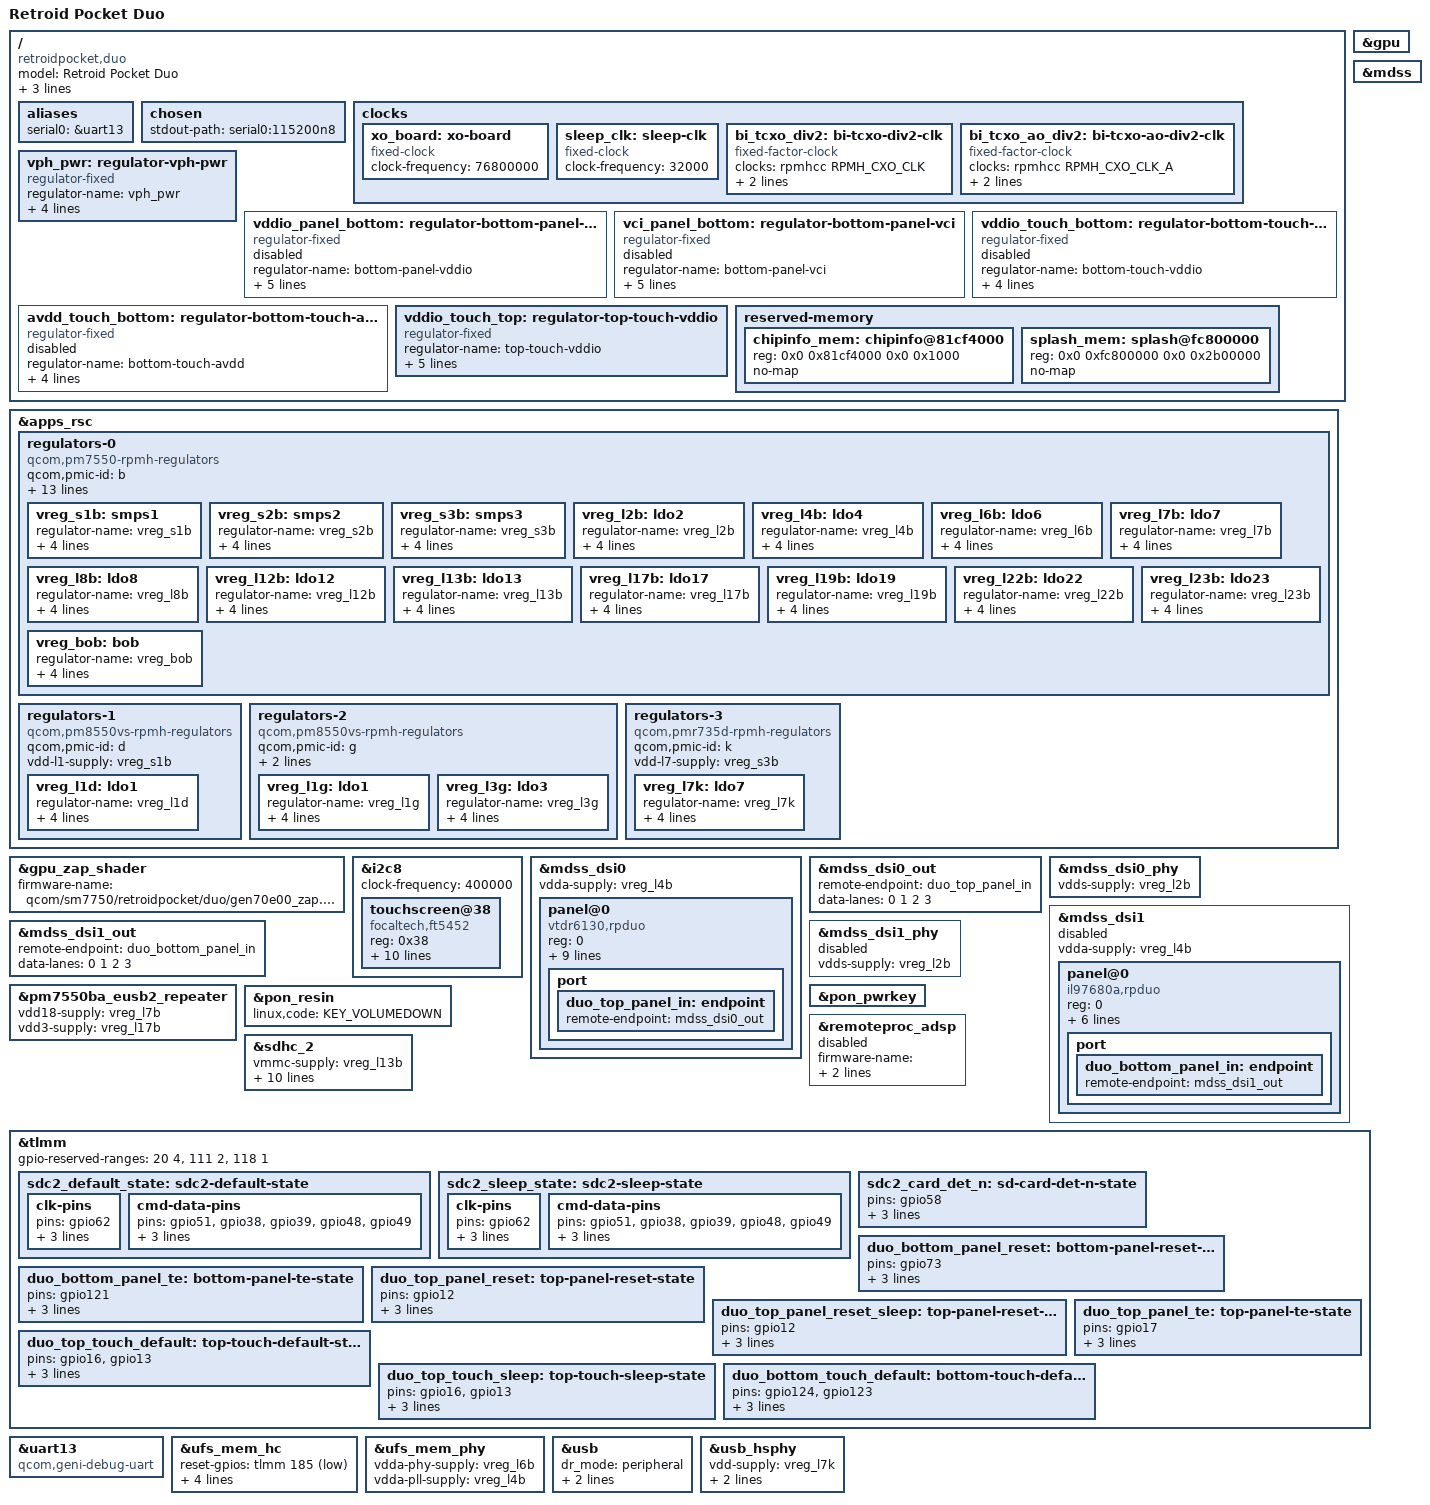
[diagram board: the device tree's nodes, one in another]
// SPDX-License-Identifier: BSD-3-Clause
/*
 * Copyright (c) Qualcomm Technologies, Inc. and/or its subsidiaries.
 * Copyright (c) 2026 Armada contributors.
 *
 */

/dts-v1/;

#include <dt-bindings/gpio/gpio.h>
#include <dt-bindings/input/linux-event-codes.h>
#include <dt-bindings/interrupt-controller/irq.h>
#include <dt-bindings/regulator/qcom,rpmh-regulator.h>
#include "eliza.dtsi"
#include "pm7550ba-eliza.dtsi"

#define spmi_bus spmi_bus0
#include "pmk8550.dtsi"
#undef spmi_bus

/ {
	model = "Retroid Pocket Duo";
	compatible = "retroidpocket,duo", "qcom,eliza";
	chassis-type = "handset";

	qcom,msm-id = <732 0x10000>;
	qcom,board-id = <0x10008 1>;

	aliases {
		serial0 = &uart13;
	};

	chosen {
		stdout-path = "serial0:115200n8";
	};

	clocks {
		xo_board: xo-board {
			compatible = "fixed-clock";
			clock-frequency = <76800000>;
			#clock-cells = <0>;
		};

		sleep_clk: sleep-clk {
			compatible = "fixed-clock";
			clock-frequency = <32000>;
			#clock-cells = <0>;
		};

		bi_tcxo_div2: bi-tcxo-div2-clk {
			compatible = "fixed-factor-clock";
			#clock-cells = <0>;

			clocks = <&rpmhcc RPMH_CXO_CLK>;
			clock-mult = <1>;
			clock-div = <2>;
		};

		bi_tcxo_ao_div2: bi-tcxo-ao-div2-clk {
			compatible = "fixed-factor-clock";
			#clock-cells = <0>;

			clocks = <&rpmhcc RPMH_CXO_CLK_A>;
			clock-mult = <1>;
			clock-div = <2>;
		};
	};

	vph_pwr: regulator-vph-pwr {
		compatible = "regulator-fixed";
		regulator-name = "vph_pwr";
		regulator-min-microvolt = <3700000>;
		regulator-max-microvolt = <3700000>;
		regulator-always-on;
		regulator-boot-on;
	};

	vddio_panel_bottom: regulator-bottom-panel-vddio {
		compatible = "regulator-fixed";
		regulator-name = "bottom-panel-vddio";
		regulator-min-microvolt = <1800000>;
		regulator-max-microvolt = <1800000>;
		gpio = <&tlmm 69 GPIO_ACTIVE_HIGH>;
		enable-active-high;
		startup-delay-us = <233>;
		status = "disabled";
	};

	vci_panel_bottom: regulator-bottom-panel-vci {
		compatible = "regulator-fixed";
		regulator-name = "bottom-panel-vci";
		regulator-min-microvolt = <3000000>;
		regulator-max-microvolt = <3000000>;
		gpio = <&tlmm 70 GPIO_ACTIVE_HIGH>;
		enable-active-high;
		startup-delay-us = <233>;
		status = "disabled";
	};

	vddio_touch_bottom: regulator-bottom-touch-vddio {
		compatible = "regulator-fixed";
		regulator-name = "bottom-touch-vddio";
		regulator-min-microvolt = <1800000>;
		regulator-max-microvolt = <1800000>;
		gpio = <&tlmm 71 GPIO_ACTIVE_HIGH>;
		enable-active-high;
		status = "disabled";
	};

	avdd_touch_bottom: regulator-bottom-touch-avdd {
		compatible = "regulator-fixed";
		regulator-name = "bottom-touch-avdd";
		regulator-min-microvolt = <3000000>;
		regulator-max-microvolt = <3000000>;
		gpio = <&tlmm 72 GPIO_ACTIVE_HIGH>;
		enable-active-high;
		status = "disabled";
	};

	vddio_touch_top: regulator-top-touch-vddio {
		compatible = "regulator-fixed";
		regulator-name = "top-touch-vddio";
		regulator-min-microvolt = <1800000>;
		regulator-max-microvolt = <1800000>;
		gpio = <&tlmm 74 GPIO_ACTIVE_HIGH>;
		enable-active-high;
		startup-delay-us = <233>;
	};

	reserved-memory {
		chipinfo_mem: chipinfo@81cf4000 {
			reg = <0x0 0x81cf4000 0x0 0x1000>;
			no-map;
		};

		splash_mem: splash@fc800000 {
			reg = <0x0 0xfc800000 0x0 0x2b00000>;
			no-map;
		};
	};
};

/*
 * LDO parent wiring follows Eliza MTP and is unverified on the Duo,
 * except for L1D's S1B parent, which Android explicitly identifies.
 */
&apps_rsc {
	regulators-0 {
		compatible = "qcom,pm7550-rpmh-regulators";
		qcom,pmic-id = "b";

		vdd-l2-l3-supply = <&vreg_s3b>;
		vdd-l4-l5-supply = <&vreg_s2b>;
		vdd-l6-supply = <&vreg_s2b>;
		vdd-l7-supply = <&vreg_s1b>;
		vdd-l8-supply = <&vreg_s1b>;
		vdd-l12-l14-supply = <&vreg_bob>;
		vdd-l13-l16-supply = <&vreg_bob>;
		vdd-l15-l17-l18-l19-l20-l21-l22-l23-supply = <&vreg_bob>;
		vdd-s1-supply = <&vph_pwr>;
		vdd-s2-supply = <&vph_pwr>;
		vdd-s3-supply = <&vph_pwr>;
		vdd-bob-supply = <&vph_pwr>;

		vreg_s1b: smps1 {
			regulator-name = "vreg_s1b";
			regulator-min-microvolt = <1856000>;
			regulator-max-microvolt = <2040000>;
			regulator-initial-mode = <RPMH_REGULATOR_MODE_HPM>;
		};

		vreg_s2b: smps2 {
			regulator-name = "vreg_s2b";
			regulator-min-microvolt = <1256000>;
			regulator-max-microvolt = <1408000>;
			regulator-initial-mode = <RPMH_REGULATOR_MODE_HPM>;
		};

		vreg_s3b: smps3 {
			regulator-name = "vreg_s3b";
			regulator-min-microvolt = <880000>;
			regulator-max-microvolt = <1040000>;
			regulator-initial-mode = <RPMH_REGULATOR_MODE_HPM>;
		};

		vreg_l2b: ldo2 {
			regulator-name = "vreg_l2b";
			regulator-min-microvolt = <880000>;
			regulator-max-microvolt = <950000>;
			regulator-initial-mode = <RPMH_REGULATOR_MODE_HPM>;
		};

		vreg_l4b: ldo4 {
			regulator-name = "vreg_l4b";
			regulator-min-microvolt = <1200000>;
			regulator-max-microvolt = <1200000>;
			regulator-initial-mode = <RPMH_REGULATOR_MODE_HPM>;
		};

		vreg_l6b: ldo6 {
			regulator-name = "vreg_l6b";
			regulator-min-microvolt = <866000>;
			regulator-max-microvolt = <958000>;
			regulator-initial-mode = <RPMH_REGULATOR_MODE_HPM>;
		};

		vreg_l7b: ldo7 {
			regulator-name = "vreg_l7b";
			regulator-min-microvolt = <1800000>;
			regulator-max-microvolt = <2000000>;
			regulator-initial-mode = <RPMH_REGULATOR_MODE_HPM>;
		};

		vreg_l8b: ldo8 {
			regulator-name = "vreg_l8b";
			regulator-min-microvolt = <1650000>;
			regulator-max-microvolt = <2000000>;
			regulator-initial-mode = <RPMH_REGULATOR_MODE_HPM>;
		};

		vreg_l12b: ldo12 {
			regulator-name = "vreg_l12b";
			regulator-min-microvolt = <2952000>;
			regulator-max-microvolt = <2952000>;
			regulator-initial-mode = <RPMH_REGULATOR_MODE_HPM>;
		};

		vreg_l13b: ldo13 {
			regulator-name = "vreg_l13b";
			regulator-min-microvolt = <2960000>;
			regulator-max-microvolt = <2960000>;
			regulator-initial-mode = <RPMH_REGULATOR_MODE_HPM>;
		};

		vreg_l17b: ldo17 {
			regulator-name = "vreg_l17b";
			regulator-min-microvolt = <3075000>;
			regulator-max-microvolt = <3300000>;
			regulator-initial-mode = <RPMH_REGULATOR_MODE_HPM>;
		};

		vreg_l19b: ldo19 {
			regulator-name = "vreg_l19b";
			regulator-min-microvolt = <2600000>;
			regulator-max-microvolt = <3544000>;
			regulator-initial-mode = <RPMH_REGULATOR_MODE_HPM>;
		};

		vreg_l22b: ldo22 {
			regulator-name = "vreg_l22b";
			regulator-min-microvolt = <3000000>;
			regulator-max-microvolt = <3300000>;
			regulator-initial-mode = <RPMH_REGULATOR_MODE_HPM>;
		};

		vreg_l23b: ldo23 {
			regulator-name = "vreg_l23b";
			regulator-min-microvolt = <1800000>;
			regulator-max-microvolt = <2960000>;
			regulator-initial-mode = <RPMH_REGULATOR_MODE_HPM>;
		};

		vreg_bob: bob {
			regulator-name = "vreg_bob";
			regulator-min-microvolt = <3008000>;
			regulator-max-microvolt = <3960000>;
			regulator-initial-mode = <RPMH_REGULATOR_MODE_HPM>;
		};
	};

	regulators-1 {
		compatible = "qcom,pm8550vs-rpmh-regulators";
		qcom,pmic-id = "d";

		vdd-l1-supply = <&vreg_s1b>;

		vreg_l1d: ldo1 {
			regulator-name = "vreg_l1d";
			regulator-min-microvolt = <1200000>;
			regulator-max-microvolt = <1200000>;
			regulator-initial-mode = <RPMH_REGULATOR_MODE_HPM>;
		};
	};

	regulators-2 {
		compatible = "qcom,pm8550vs-rpmh-regulators";
		qcom,pmic-id = "g";

		vdd-l1-supply = <&vreg_s2b>;
		vdd-l3-supply = <&vreg_s2b>;

		vreg_l1g: ldo1 {
			regulator-name = "vreg_l1g";
			regulator-min-microvolt = <1150000>;
			regulator-max-microvolt = <1250000>;
			regulator-initial-mode = <RPMH_REGULATOR_MODE_HPM>;
		};

		vreg_l3g: ldo3 {
			regulator-name = "vreg_l3g";
			regulator-min-microvolt = <1200000>;
			regulator-max-microvolt = <1304000>;
			regulator-initial-mode = <RPMH_REGULATOR_MODE_HPM>;
		};
	};

	regulators-3 {
		compatible = "qcom,pmr735d-rpmh-regulators";
		qcom,pmic-id = "k";

		vdd-l7-supply = <&vreg_s3b>;

		vreg_l7k: ldo7 {
			regulator-name = "vreg_l7k";
			regulator-min-microvolt = <880000>;
			regulator-max-microvolt = <880000>;
			regulator-initial-mode = <RPMH_REGULATOR_MODE_HPM>;
		};
	};
};

&gpu {
	status = "okay";
};

&gpu_zap_shader {
	firmware-name = "qcom/sm7750/retroidpocket/duo/gen70e00_zap.mbn";
};

&i2c8 {
	clock-frequency = <400000>;
	status = "okay";

	touchscreen@38 {
		compatible = "focaltech,ft5452";
		reg = <0x38>;
		label = "top_touchscreen";

		interrupt-parent = <&tlmm>;
		interrupts = <13 IRQ_TYPE_LEVEL_LOW>;
		reset-gpios = <&tlmm 16 GPIO_ACTIVE_LOW>;

		vcc-supply = <&vreg_l22b>;
		iovcc-supply = <&vddio_touch_top>;

		pinctrl-0 = <&duo_top_touch_default>;
		pinctrl-1 = <&duo_top_touch_sleep>;
		pinctrl-names = "default", "sleep";

		touchscreen-size-x = <1080>;
		touchscreen-size-y = <1920>;
	};
};

&mdss {
	status = "okay";
};

&mdss_dsi0 {
	vdda-supply = <&vreg_l4b>;
	status = "okay";

	panel@0 {
		compatible = "vtdr6130,rpduo";
		reg = <0>;

		vddio-supply = <&vreg_l8b>;
		vci-supply = <&vreg_l19b>;
		vdd-supply = <&vreg_l1g>;
		reset-gpios = <&tlmm 12 GPIO_ACTIVE_LOW>;
		rotation = <180>;

		pinctrl-0 = <&duo_top_panel_reset>, <&duo_top_panel_te>;
		pinctrl-1 = <&duo_top_panel_reset_sleep>, <&duo_top_panel_te>;
		pinctrl-names = "default", "sleep";

		port {
			duo_top_panel_in: endpoint {
				remote-endpoint = <&mdss_dsi0_out>;
			};
		};
	};
};

&mdss_dsi0_out {
	remote-endpoint = <&duo_top_panel_in>;
	data-lanes = <0 1 2 3>;
};

&mdss_dsi0_phy {
	vdds-supply = <&vreg_l2b>;
	status = "okay";
};

&mdss_dsi1 {
	vdda-supply = <&vreg_l4b>;
	status = "disabled";

	panel@0 {
		compatible = "il97680a,rpduo";
		reg = <0>;

		vddio-supply = <&vddio_panel_bottom>;
		vci-supply = <&vci_panel_bottom>;
		vdd-supply = <&vreg_l1g>;
		reset-gpios = <&tlmm 73 GPIO_ACTIVE_LOW>;

		pinctrl-0 = <&duo_bottom_panel_reset>, <&duo_bottom_panel_te>;
		pinctrl-names = "default";

		port {
			duo_bottom_panel_in: endpoint {
				remote-endpoint = <&mdss_dsi1_out>;
			};
		};
	};
};

&mdss_dsi1_out {
	remote-endpoint = <&duo_bottom_panel_in>;
	data-lanes = <0 1 2 3>;
};

&mdss_dsi1_phy {
	vdds-supply = <&vreg_l2b>;
	status = "disabled";
};

&pm7550ba_eusb2_repeater {
	vdd18-supply = <&vreg_l7b>;
	vdd3-supply = <&vreg_l17b>;
};

&pon_pwrkey {
	status = "okay";
};

&pon_resin {
	linux,code = <KEY_VOLUMEDOWN>;
	status = "okay";
};

&remoteproc_adsp {
	firmware-name = "qcom/sm7750/retroidpocket/duo/adsp.mbn",
			"qcom/sm7750/retroidpocket/duo/adsp_dtb.mbn";
	status = "disabled";
};

&sdhc_2 {
	vmmc-supply = <&vreg_l13b>;
	vqmmc-supply = <&vreg_l23b>;
	cd-gpios = <&tlmm 58 GPIO_ACTIVE_LOW>;
	pinctrl-0 = <&sdc2_default_state &sdc2_card_det_n>;
	pinctrl-1 = <&sdc2_sleep_state &sdc2_card_det_n>;
	pinctrl-names = "default", "sleep";
	bus-width = <4>;
	cap-sd-highspeed;
	max-frequency = <50000000>;
	no-1-8-v;
	no-mmc;
	no-sdio;
	status = "okay";
};

&tlmm {
	gpio-reserved-ranges = <20 4>, <111 2>, <118 1>;

	sdc2_default_state: sdc2-default-state {
		clk-pins {
			pins = "gpio62";
			function = "sdc2";
			drive-strength = <16>;
			bias-disable;
		};

		cmd-data-pins {
			pins = "gpio51", "gpio38", "gpio39", "gpio48", "gpio49";
			function = "sdc2";
			drive-strength = <10>;
			bias-pull-up;
		};
	};

	sdc2_sleep_state: sdc2-sleep-state {
		clk-pins {
			pins = "gpio62";
			function = "gpio";
			drive-strength = <2>;
			bias-disable;
		};

		cmd-data-pins {
			pins = "gpio51", "gpio38", "gpio39", "gpio48", "gpio49";
			function = "gpio";
			drive-strength = <2>;
			bias-pull-up;
		};
	};

	sdc2_card_det_n: sd-card-det-n-state {
		pins = "gpio58";
		function = "gpio";
		drive-strength = <2>;
		bias-pull-up;
	};

	duo_bottom_panel_reset: bottom-panel-reset-state {
		pins = "gpio73";
		function = "gpio";
		drive-strength = <2>;
		bias-pull-up;
	};

	duo_bottom_panel_te: bottom-panel-te-state {
		pins = "gpio121";
		function = "mdp_vsync";
		drive-strength = <2>;
		bias-pull-down;
	};

	duo_top_panel_reset: top-panel-reset-state {
		pins = "gpio12";
		function = "gpio";
		drive-strength = <8>;
		bias-disable;
	};

	duo_top_panel_reset_sleep: top-panel-reset-sleep-state {
		pins = "gpio12";
		function = "gpio";
		drive-strength = <2>;
		bias-pull-down;
	};

	duo_top_panel_te: top-panel-te-state {
		pins = "gpio17";
		function = "mdp_vsync";
		drive-strength = <2>;
		bias-pull-down;
	};

	duo_top_touch_default: top-touch-default-state {
		pins = "gpio16", "gpio13";
		function = "gpio";
		drive-strength = <8>;
		bias-pull-up;
	};

	duo_top_touch_sleep: top-touch-sleep-state {
		pins = "gpio16", "gpio13";
		function = "gpio";
		drive-strength = <2>;
		bias-pull-down;
	};

	duo_bottom_touch_default: bottom-touch-default-state {
		pins = "gpio124", "gpio123";
		function = "gpio";
		drive-strength = <8>;
		bias-pull-up;
	};
};

&uart13 {
	compatible = "qcom,geni-debug-uart";
	status = "okay";
};

&ufs_mem_hc {
	reset-gpios = <&tlmm 185 GPIO_ACTIVE_LOW>;
	vcc-supply = <&vreg_l12b>;
	vcc-max-microamp = <800000>;
	vccq2-supply = <&vreg_l1d>;
	vccq2-max-microamp = <750000>;
	/* Android votes L3G for vddp-ref-clk; mainline supply handling is unresolved. */
	status = "okay";
};

&ufs_mem_phy {
	vdda-phy-supply = <&vreg_l6b>;
	vdda-pll-supply = <&vreg_l4b>;
	/* Android votes L2B for vdda-qref; mainline supply handling is unresolved. */
	status = "okay";
};

&usb {
	/delete-property/ usb-role-switch;
	dr_mode = "peripheral";
	maximum-speed = "high-speed";
	phys = <&usb_hsphy>;
	phy-names = "usb2-phy";
	status = "okay";
};

&usb_hsphy {
	vdd-supply = <&vreg_l7k>;
	vdda12-supply = <&vreg_l4b>;
	phys = <&pm7550ba_eusb2_repeater>;
	status = "okay";
};
